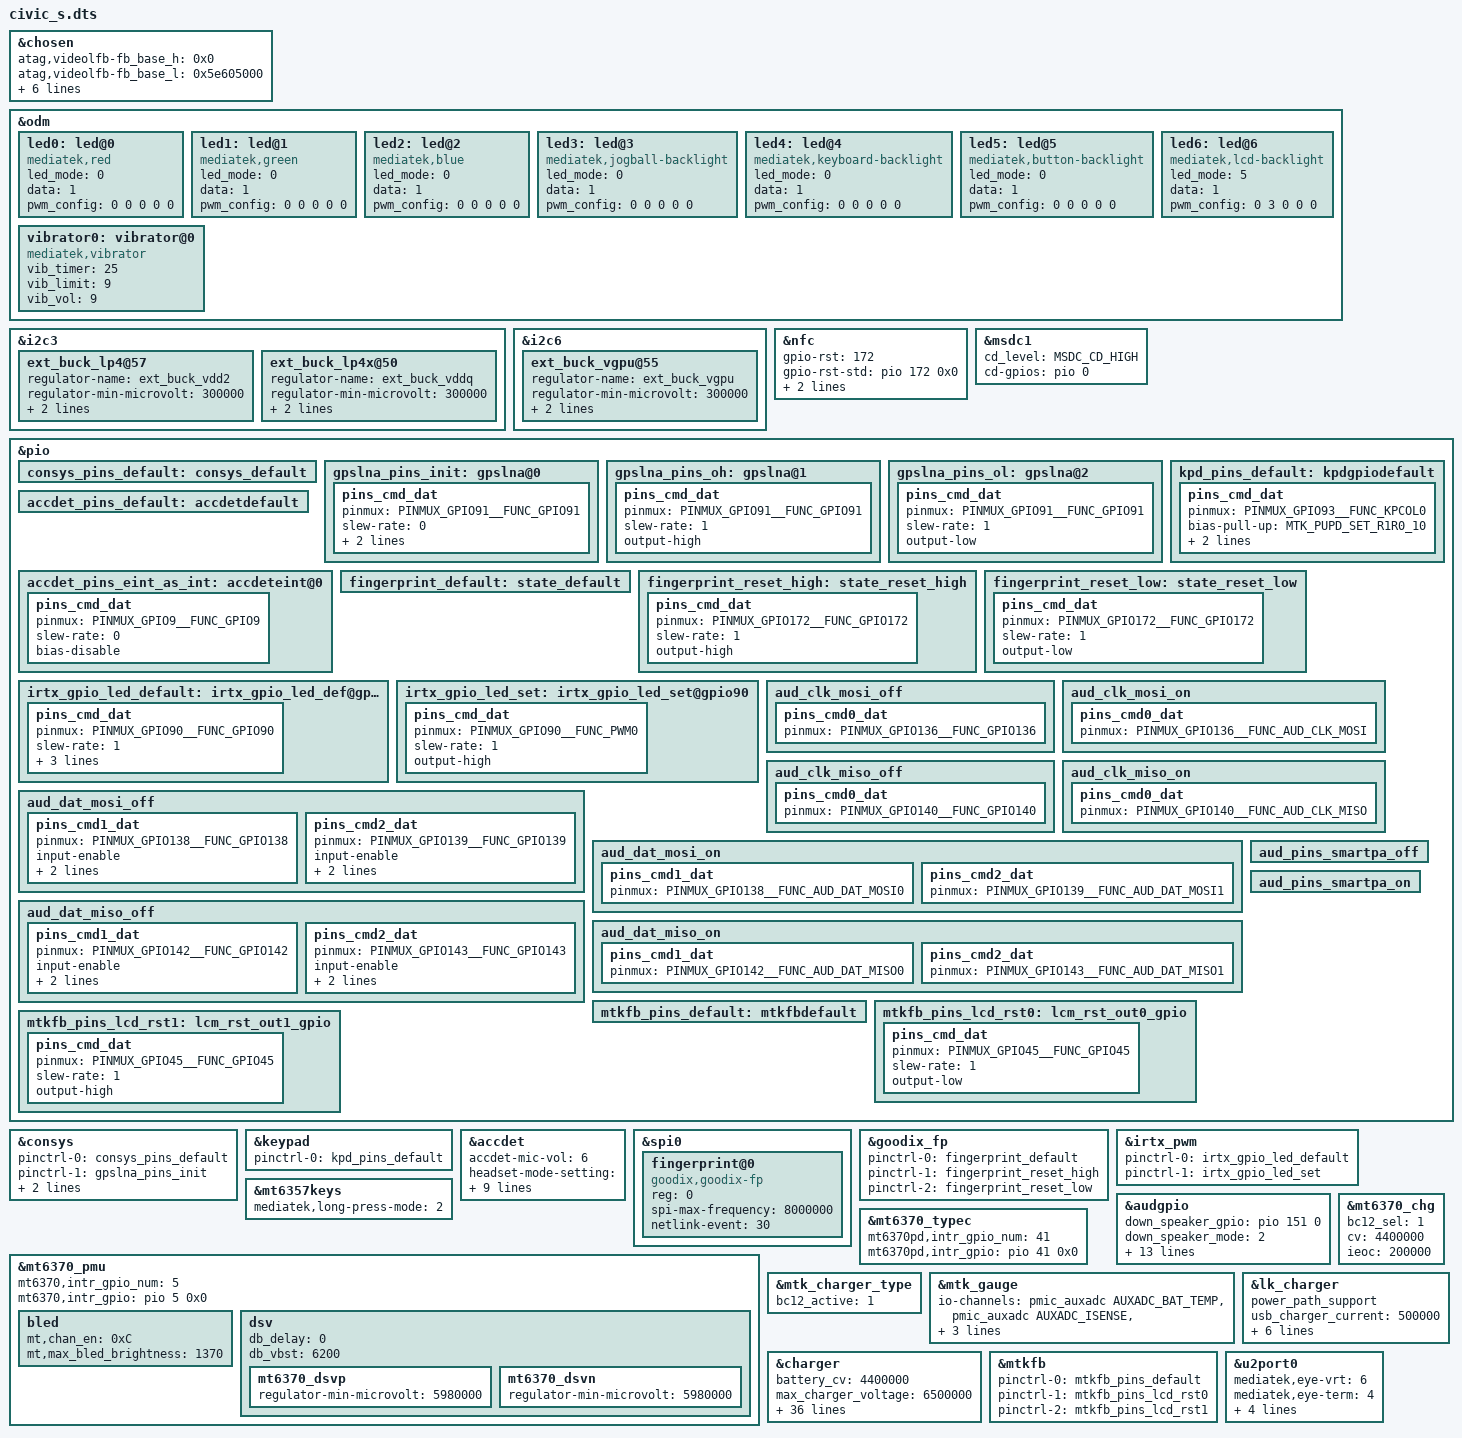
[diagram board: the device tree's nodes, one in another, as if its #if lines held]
// SPDX-License-Identifier: GPL-2.0+

#include <dt-bindings/interrupt-controller/arm-gic.h>
#include <dt-bindings/interrupt-controller/irq.h>
#include <dt-bindings/pinctrl/mt6765-pinfunc.h>
#include <dt-bindings/clock/mt6765-clk.h>
#include <dt-bindings/mmc/mt6765-msdc.h>

/dts-v1/;
/plugin/;

/* chosen */
&chosen {

	/* fpga may has no lk, we need to specify display info here */
	/* fb buffer is reserved using this dts by memory node above */
	atag,videolfb-fb_base_h = <0x0>;
	atag,videolfb-fb_base_l = <0x5e605000>;
	atag,videolfb-islcmfound = <1>;
	/* because no lk, so lcm is not inited */
	atag,videolfb-islcm_inited = <0>;
	atag,videolfb-fps= <6000>;
	atag,videolfb-vramSize= <0x017bb000>;
//Begin modified by yan.gong for CIVIC-3002 on 2022-07-12
	atag,videolfb-lcmname= "icnl9916_hdplus1612_dsi_vdo_dzx_xe665";
//End modified by yan.gong for CIVIC-3002 on 2022-07-12
};

&odm {
	led0:led@0 {
		compatible = "mediatek,red";
		led_mode = <0>;
		data = <1>;
		pwm_config = <0 0 0 0 0>;
	};
	led1:led@1 {
		compatible = "mediatek,green";
		led_mode = <0>;
		data = <1>;
		pwm_config = <0 0 0 0 0>;
	};
	led2:led@2 {
		compatible = "mediatek,blue";
		led_mode = <0>;
		data = <1>;
		pwm_config = <0 0 0 0 0>;
	};
	led3:led@3 {
		compatible = "mediatek,jogball-backlight";
		led_mode = <0>;
		data = <1>;
		pwm_config = <0 0 0 0 0>;
	};
	led4:led@4 {
		compatible = "mediatek,keyboard-backlight";
		led_mode = <0>;
		data = <1>;
		pwm_config = <0 0 0 0 0>;
	};
	led5:led@5 {
		compatible = "mediatek,button-backlight";
		led_mode = <0>;
		data = <1>;
		pwm_config = <0 0 0 0 0>;
	};
	led6:led@6 {
		compatible = "mediatek,lcd-backlight";
		led_mode = <5>;
		data = <1>;
		pwm_config = <0 3 0 0 0>;
	};
	vibrator0:vibrator@0 {
		compatible = "mediatek,vibrator";
		vib_timer = <25>;
		vib_limit = <9>;
		vib_vol= <9>;
	};
};

&i2c3 {
	ext_buck_lp4@57 {
		regulator-name ="ext_buck_vdd2";
		regulator-min-microvolt = <300000>;
		regulator-max-microvolt = <1300000>;
		vsel_pin = <0>;
	};

	ext_buck_lp4x@50 {
		regulator-name ="ext_buck_vddq";
		regulator-min-microvolt = <300000>;
		regulator-max-microvolt = <1300000>;
		vsel_pin = <1>;
	};
};

&i2c6 {
	ext_buck_vgpu@55 {
		regulator-name ="ext_buck_vgpu";
		regulator-min-microvolt = <300000>;
		regulator-max-microvolt = <1300000>;
		vsel_pin = <2>;
	};
};

//Begin add by na.long for task11386747 porting  on 2021/07/27
&nfc {
	gpio-rst = <172>;
	gpio-rst-std = <&pio 172 0x0>;
	gpio-irq = <10>;
	gpio-irq-std = <&pio 10 0x0>;
};
//end add by na.long for task11386747 porting  on 2021/07/27

//Begin added by yan.gong for CIVIC-3003 on 2022-07-12
&msdc1 {
       cd_level = /bits/ 8 <MSDC_CD_HIGH>;
       cd-gpios = <&pio 0 0>;
};

//End added by yan.gong for CIVIC-3003 on 2022-07-12

/* CONSYS GPIO standardization */
&pio {
	consys_pins_default: consys_default {
	};
	gpslna_pins_init: gpslna@0 {
		pins_cmd_dat {
			pinmux = <PINMUX_GPIO91__FUNC_GPIO91>;
			slew-rate = <0>;
			bias-disable;
			output-low;
		};
	};
	gpslna_pins_oh: gpslna@1 {
		pins_cmd_dat {
			pinmux = <PINMUX_GPIO91__FUNC_GPIO91>;
			slew-rate = <1>;
			output-high;
		};
	};
	gpslna_pins_ol: gpslna@2 {
		pins_cmd_dat {
			pinmux = <PINMUX_GPIO91__FUNC_GPIO91>;
			slew-rate = <1>;
			output-low;
		};
	};
};
&consys {
	pinctrl-names = "default", "gps_lna_state_init",
		"gps_lna_state_oh", "gps_lna_state_ol";
	pinctrl-0 = <&consys_pins_default>;
	pinctrl-1 = <&gpslna_pins_init>;
	pinctrl-2 = <&gpslna_pins_oh>;
	pinctrl-3 = <&gpslna_pins_ol>;
	status = "okay";
};
/* CONSYS end */

&keypad {
	pinctrl-names = "default";
	pinctrl-0 = <&kpd_pins_default>;
};

&pio {
	kpd_pins_default: kpdgpiodefault {
		pins_cmd_dat {
			pinmux = <PINMUX_GPIO93__FUNC_KPCOL0>;
			bias-pull-up = <MTK_PUPD_SET_R1R0_10>;
			output-low;
			input-schmitt-enable;
		};
	};
};


/* accdet start */
&accdet {
	accdet-mic-vol = <6>;
	headset-mode-setting = <0x500 0x500 1 0x1f0 0x800 0x800 0x20 0x44>;
	accdet-plugout-debounce = <1>;
	accdet-mic-mode = <1>;
	headset-eint-level-pol = <8>;
	headset-three-key-threshold = <0 80 220 400>;
	headset-three-key-threshold-CDD = <0 121 192 600>;
	headset-four-key-threshold = <0 58 121 192 400>;
	pinctrl-names = "default", "state_eint_as_int";
	pinctrl-0 = <&accdet_pins_default>;
	pinctrl-1 = <&accdet_pins_eint_as_int>;
	status = "okay";
};
&pio {
	accdet_pins_default: accdetdefault {
	};
	accdet_pins_eint_as_int: accdeteint@0 {
		pins_cmd_dat {
			pinmux = <PINMUX_GPIO9__FUNC_GPIO9>;
			slew-rate = <0>;
			bias-disable;
		};
	};
};
/* accdet end */

/* FINGERPRINT start */
&spi0 {
	#address-cells = <1>;
	#size-cells = <0>;
	fingerprint@0 {
		compatible = "goodix,goodix-fp";
		reg = <0>;
		spi-max-frequency = <8000000>;
		netlink-event = <30>;
		status = "okay";
	};
};

&goodix_fp {
	pinctrl-names = "default", "reset_high", "reset_low";
	pinctrl-0 = <&fingerprint_default>;
	pinctrl-1 = <&fingerprint_reset_high>;
	pinctrl-2 = <&fingerprint_reset_low>;
	status = "okay";
};

&pio {
	fingerprint_default: state_default {
	};
	fingerprint_reset_high: state_reset_high {
		pins_cmd_dat {
			pinmux = <PINMUX_GPIO172__FUNC_GPIO172>;
			slew-rate = <1>;
			output-high;
		};
	};
	fingerprint_reset_low: state_reset_low {
		pins_cmd_dat {
			pinmux = <PINMUX_GPIO172__FUNC_GPIO172>;
			slew-rate = <1>;
			output-low;
		};
	};
};
/* FINGERPRINT end */

/* IRTX GPIO end */
&irtx_pwm {
	pinctrl-names = "irtx_gpio_led_default", "irtx_gpio_led_set";
	pinctrl-0 = <&irtx_gpio_led_default>;
	pinctrl-1 = <&irtx_gpio_led_set>;
	status = "okay";
};
&pio {
	irtx_gpio_led_default:irtx_gpio_led_def@gpio90 {
		pins_cmd_dat {
			pinmux = <PINMUX_GPIO90__FUNC_GPIO90>;
			slew-rate = <1>;
			bias-disable;
			output-low;
			input-schmitt-enable = <0>;
		};
	};

	irtx_gpio_led_set:irtx_gpio_led_set@gpio90 {
		pins_cmd_dat {
			pinmux = <PINMUX_GPIO90__FUNC_PWM0>;
			slew-rate = <1>;
			output-high;
		};
	};
};
/* IRTX GPIO Settings -End */

/* AUDIO GPIO standardization */
&audgpio {
//Begin added by liangjiaqiang for CIVIC-3069 on 2022-07-13
	down_speaker_gpio = <&pio 151 0>;
	down_speaker_mode = <2>;
	
	up_speaker_gpio = <&pio 150 0>;
	up_pa_speaker_mode = <2>;
	up_pa_voice_mode = <5>;
//End added by liangjiaqiang for CIVIC-3069 on 2022-07-13
	pinctrl-names = "aud_clk_mosi_off",
			"aud_clk_mosi_on",
			"aud_clk_miso_off",
			"aud_clk_miso_on",
			"aud_dat_mosi_off",
			"aud_dat_mosi_on",
			"aud_dat_miso_off",
			"aud_dat_miso_on",
			"aud_smartpa_off",
			"aud_smartpa_on";
	pinctrl-0 = <&aud_clk_mosi_off>;
	pinctrl-1 = <&aud_clk_mosi_on>;
	pinctrl-2 = <&aud_clk_miso_off>;
	pinctrl-3 = <&aud_clk_miso_on>;
	pinctrl-4 = <&aud_dat_mosi_off>;
	pinctrl-5 = <&aud_dat_mosi_on>;
	pinctrl-6 = <&aud_dat_miso_off>;
	pinctrl-7 = <&aud_dat_miso_on>;
	pinctrl-8 = <&aud_pins_smartpa_off>;
	pinctrl-9 = <&aud_pins_smartpa_on>;
	status = "okay";
};

&pio {
	aud_clk_mosi_off: aud_clk_mosi_off {
		pins_cmd0_dat {
			pinmux = <PINMUX_GPIO136__FUNC_GPIO136>;
		};
	};

	aud_clk_mosi_on: aud_clk_mosi_on {
		pins_cmd0_dat {
			pinmux = <PINMUX_GPIO136__FUNC_AUD_CLK_MOSI>;
		};
	};

	aud_clk_miso_off: aud_clk_miso_off {
		pins_cmd0_dat {
			pinmux = <PINMUX_GPIO140__FUNC_GPIO140>;
		};
	};

	aud_clk_miso_on: aud_clk_miso_on {
		pins_cmd0_dat {
			pinmux = <PINMUX_GPIO140__FUNC_AUD_CLK_MISO>;
		};
	};

	aud_dat_mosi_off: aud_dat_mosi_off {
		pins_cmd1_dat {
			pinmux = <PINMUX_GPIO138__FUNC_GPIO138>;
			input-enable;
			slew-rate = <0>;
			bias-disable;
		};
		pins_cmd2_dat {
			pinmux = <PINMUX_GPIO139__FUNC_GPIO139>;
			input-enable;
			slew-rate = <0>;
			bias-disable;
		};
	};

	aud_dat_mosi_on: aud_dat_mosi_on {
		pins_cmd1_dat {
			pinmux = <PINMUX_GPIO138__FUNC_AUD_DAT_MOSI0>;
		};
		pins_cmd2_dat {
			pinmux = <PINMUX_GPIO139__FUNC_AUD_DAT_MOSI1>;
		};
	};

	aud_dat_miso_off: aud_dat_miso_off {
		pins_cmd1_dat {
			pinmux = <PINMUX_GPIO142__FUNC_GPIO142>;
			input-enable;
			slew-rate = <0>;
			bias-disable;
		};
		pins_cmd2_dat {
			pinmux = <PINMUX_GPIO143__FUNC_GPIO143>;
			input-enable;
			slew-rate = <0>;
			bias-disable;
		};
	};

	aud_dat_miso_on: aud_dat_miso_on {
		pins_cmd1_dat {
			pinmux = <PINMUX_GPIO142__FUNC_AUD_DAT_MISO0>;
		};
		pins_cmd2_dat {
			pinmux = <PINMUX_GPIO143__FUNC_AUD_DAT_MISO1>;
		};
	};

	aud_pins_smartpa_off: aud_pins_smartpa_off {
	};

	aud_pins_smartpa_on: aud_pins_smartpa_on {
	};
};
/* AUDIO end */
//Begin add by tangshan.bai for CIVIC-3144 on 2022-07-20
&mt6357keys {
#if defined(TARGET_BUILD_MMITEST) || defined(TARGET_BUILD_CERTIFICATION) || defined(TARGET_BUILD_GCF)
     mediatek,long-press-mode = <2>;
#else
     mediatek,long-press-mode = <1>;
#endif
};
//End add by tangshan.bai for CIVIC-3144 on 2022-07-20

&mt6370_pmu {
//Begin modified by liangjiaqiang for CIVIC-3107 on 2022-07-12
	mt6370,intr_gpio_num = <5>; /* direct defined GPIO num */
	mt6370,intr_gpio = <&pio 5 0x0>;
//End modified by liangjiaqiang for CIVIC-3107 on 2022-07-12
//Begin modified by liangjiaqiang for CIVIC-3084 on 2022-07-12
	bled {
       //Begin modified by liangjiaqiang for CIVIC-3266 on 2022-08-01
               mt,chan_en  = <0xC>; /* bit 0 1 2 3 -> chan 1 2 3 4 */
       //End modified by liangjiaqiang for CIVIC-3266 on 2022-08-01
		/* we have 11 bit resolution, quantize in driver */
		mt,max_bled_brightness = <1370>; /* maximum 2047 */
	};

	dsv {
		db_delay = <0>;	/* 0 = no constraint */
				/* 1 = 0ms */
				/* 2 = 1ms */
				/* 3 = 4ms */

		db_vbst  = <6200>;      /* mV */

		mt6370_dsvp {
			regulator-min-microvolt = <5980000>;
		};

		mt6370_dsvn {
			regulator-min-microvolt = <5980000>;
		};
	};

//End modified by liangjiaqiang for CIVIC-3084 on 2022-07-12

};

&mt6370_typec {
	mt6370pd,intr_gpio_num = <41>; /* direct defined GPIO num */
	mt6370pd,intr_gpio = <&pio 41 0x0>;
};

&mt6370_chg {
	bc12_sel = <1>;
//Begin added by zhangkun for CIVIC-4068 on 2022-08-24
	cv = <4400000>;
	ieoc = <200000>;
//Begin added by zhangkun for CIVIC-4068 on 2022-08-24
};
//begin modify by tangshan.bai for CIVICPL-3428 on 2022-07-31
&mtk_charger_type {
	bc12_active = <1>;
};
//End modify by tangshan.bai for CIVICPL-3428 on 2022-07-31
//Begin added by liangjiaqiang for CIVIC-3107 on 2022-07-13
//Begin added by tangshan for CIVIC-3103 on 2022-08-05
#include <dt-bindings/iio/mt635x-auxadc.h>
&mtk_gauge{
	io-channels =
			<&pmic_auxadc AUXADC_BAT_TEMP>,
			<&pmic_auxadc AUXADC_ISENSE>,
			<&pmic_auxadc AUXADC_VBIF>,
			<&pmic_auxadc AUXADC_IMP>,
			<&pmic_auxadc AUXADC_IMIX_R>,
			<&auxadc 3>;
	io-channel-names = "pmic_battery_temp",
			"pmic_battery_voltage",
			"pmic_bif_voltage",
			"pmic_ptim_voltage",
			"pmic_ptim_r",
			"battery_id";
};

&lk_charger {
	power_path_support;
//Begin added by zhangkun for CIVIC-4068 on 2022-08-24
	/* charging current */
	usb_charger_current = <500000>;
	ac_charger_current = <1000000>;
	ac_charger_input_current = <1000000>;
	non_std_ac_charger_current = <500000>;
	charging_host_charger_current = <1000000>;
	ta_ac_charger_current = <1000000>;
	pd_charger_current = <1000000>;
//End added by zhangkun for CIVIC-4068 on 2022-08-24
};
&charger {
	/* common */
	battery_cv = <4400000>;
	max_charger_voltage = <6500000>;
	min_charger_voltage = <4400000>;
	power_path_support;
	charger = <&mtk_charger_type>; // modify by tangshan.bai for CIVICPL-3353 202-09-02

        //Begin modify by tangshan.bai for CIVIC-3985 on 2022-08-26
        enable_sw_jeita;
	jeita_temp_above_t4_cv = <4100000>;
	jeita_temp_t3_to_t4_cv = <4100000>;
	jeita_temp_t2_to_t3_cv = <4400000>;
	jeita_temp_t1_to_t2_cv = <4400000>;
	jeita_temp_t0_to_t1_cv = <4400000>;
	jeita_temp_below_t0_cv = <4400000>;
        temp_t4_thres = <55>;
	temp_t4_thres_minus_x_degree = <51>;
	temp_t3_thres = <42>;
	temp_t3_thres_minus_x_degree = <43>;
	temp_t2_thres = <11>;
	temp_t2_thres_plus_x_degree = <10>;
	temp_t1_thres = <1>;
	temp_t1_thres_plus_x_degree = <0>;
	temp_t0_thres = <1>;
	temp_t0_thres_plus_x_degree = <0>;
	temp_neg_10_thres = <1>;
	jeita_temp_above_t4_current = <0>;
//Begin added by zhangkun for CIVIC-4068 on 2022-08-24
	jeita_temp_t3_to_t4_current = <1500000>;
	jeita_temp_t2_to_t3_current = <2100000>;
	jeita_temp_t1_to_t2_current = <1000000>;
	jeita_temp_t0_to_t1_current = <1000000>;
	jeita_temp_below_t0_current = <0>;
        //End modify by tangshan.bai for CIVIC-3985 on 2022-08-26

	/* battery temperature protection */
	enable_min_charge_temp;
	min_charge_temp = <0>;
	min_charge_temp_plus_x_degree = <2>;
	max_charge_temp = <55>;
	max_charge_temp_minus_x_degree = <53>;

	/* charging current */
	ac_charger_current = <2100000>;
	ac_charger_input_current = <2100000>;
	charging_host_charger_current = <1300000>;

	/* dynamic mivr */
	max_dmivr_charger_current = <2100000>;
//End added by zhangkun for CIVIC-4068 on 2022-08-24
};


//Begin added by yan.gong for CIVIC on 2022-08-05
//add for lcm configure
&mtkfb {
	pinctrl-names = "default","lcm_rst_out0_gpio","lcm_rst_out1_gpio";
	pinctrl-0 = <&mtkfb_pins_default>;
	pinctrl-1 = <&mtkfb_pins_lcd_rst0>;
	pinctrl-2 = <&mtkfb_pins_lcd_rst1>;
	status = "okay";
};
&pio {
	mtkfb_pins_default: mtkfbdefault {
	};

	mtkfb_pins_lcd_rst0: lcm_rst_out0_gpio {
		pins_cmd_dat {
			pinmux = <PINMUX_GPIO45__FUNC_GPIO45>;
			slew-rate = <1>;
			output-low;
		};
	};

	mtkfb_pins_lcd_rst1: lcm_rst_out1_gpio {
		pins_cmd_dat {
			pinmux = <PINMUX_GPIO45__FUNC_GPIO45>;
			slew-rate = <1>;
			output-high;
		};
	};

};

//Begain modified by zhangkun for CIVIC-4368/CIVIC-4509 on 2022-08-31
&u2port0 {
    mediatek,eye-vrt=<6>;
    mediatek,eye-term=<4>;
    mediatek,eye-rev6=<2>;

    mediatek,host-eye-vrt=<7>;
    mediatek,host-eye-term=<1>;
    mediatek,host-eye-rev6=<3>;
};
//End modified by zhangkun for CIVIC-4368/CIVIC-4509 on 2022-08-31

//End added by yan.gong for CIVIC on 2022-08-05
#include "bat_setting/civic_s/civic_mt6765_battery_prop.dtsi"
//End added by tangshan for CIVIC-3103 on 2022-08-05

#include <civic_s/cust.dtsi>
//Begain modified by chengyixuan for CIVIC-3005 on 2022-07-12
#include "cust_mt6765_civi_camera.dtsi"
//End modified by chengyixuan for CIVIC-3005 on 2022-07-12
#include "cust_mt6765_touch_civi.dtsi"
/*End of this file, DO NOT ADD ANYTHING HERE*/
